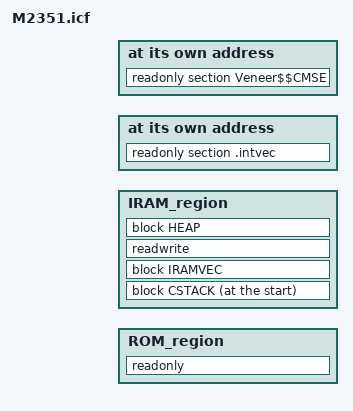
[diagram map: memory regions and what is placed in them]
/*
 * Copyright (c) 2019-2020, Nuvoton Technology Corporation
 *
 * SPDX-License-Identifier: Apache-2.0
 *
 * Licensed under the Apache License, Version 2.0 (the "License");
 * you may not use this file except in compliance with the License.
 * You may obtain a copy of the License at
 *
 *     http://www.apache.org/licenses/LICENSE-2.0
 *
 * Unless required by applicable law or agreed to in writing, software
 * distributed under the License is distributed on an "AS IS" BASIS,
 * WITHOUT WARRANTIES OR CONDITIONS OF ANY KIND, either express or implied.
 * See the License for the specific language governing permissions and
 * limitations under the License.
 */

/*###ICF### Section handled by ICF editor, don't touch! ****/
/*-Editor annotation file-*/
/* IcfEditorFile="$TOOLKIT_DIR$\config\ide\IcfEditor\cortex_v1_0.xml" */

include "../partition_M2351_mem.icf";

if (! isdefinedsymbol(NU_TZ_NSC_SIZE)) {
    define symbol NU_TZ_NSC_SIZE    = 0x1000;
}

if (isdefinedsymbol(DOMAIN_NS)) {

    if (! isdefinedsymbol(MBED_APP_START)) {
        define symbol MBED_APP_START                = NU_ROM_START_NS;
    }

    if (! isdefinedsymbol(MBED_APP_SIZE)) {
        define symbol MBED_APP_SIZE                 = NU_ROM_SIZE_NS;
    }

    if (! isdefinedsymbol(MBED_RAM_APP_START)) {
        define symbol MBED_RAM_APP_START            = NU_RAM_START_NS;
    }

    if (! isdefinedsymbol(MBED_RAM_APP_SIZE)) {
        define symbol MBED_RAM_APP_SIZE             = NU_RAM_SIZE_NS;
    }

    if (! isdefinedsymbol(MBED_BOOT_STACK_SIZE)) {
        define symbol MBED_BOOT_STACK_SIZE          = 0x400;
    }
    
    /*-Specials-*/
    define symbol __ICFEDIT_intvec_start__          = MBED_APP_START;
    /*-Memory Regions-*/
    define symbol __ICFEDIT_region_ROM_start__      = MBED_APP_START;
    define symbol __ICFEDIT_region_ROM_end__        = MBED_APP_START + MBED_APP_SIZE - 1;
    define symbol __ICFEDIT_region_IRAM_start__     = MBED_RAM_APP_START;
    define symbol __ICFEDIT_region_IRAM_end__       = MBED_RAM_APP_START + MBED_RAM_APP_SIZE - 1;
    
    /*-Sizes-*/
    define symbol __ICFEDIT_size_cstack__           = MBED_BOOT_STACK_SIZE;
    define symbol __ICFEDIT_size_heap__             = 0x8000;

} else {

    if (! isdefinedsymbol(MBED_APP_START)) {
        define symbol MBED_APP_START                = NU_ROM_START_S;
    }

    if (! isdefinedsymbol(MBED_APP_SIZE)) {
        define symbol MBED_APP_SIZE                 = NU_ROM_SIZE_S;
    }

    if (! isdefinedsymbol(MBED_RAM_APP_START)) {
        define symbol MBED_RAM_APP_START            = NU_RAM_START_S;
    }

    if (! isdefinedsymbol(MBED_RAM_APP_SIZE)) {
        define symbol MBED_RAM_APP_SIZE             = NU_RAM_SIZE_S;
    }

    if (! isdefinedsymbol(MBED_BOOT_STACK_SIZE)) {
        define symbol MBED_BOOT_STACK_SIZE          = 0x400;
    }

    /* Requirements for NSC location
     *
     * 1. By IDAU, 0~0x4000 is secure. NSC can only locate in 0x4000~0x10000000.
     * 2. Greentea flash IAP uses last 4 sectors for its test. Avoid this range.
     * 3. Greentea NVSTORE uses last 2 sectors or 4KiB x 2 for its test. Avoid this range.
     * 4. NSC region size defaults to 4KiB if not defined.
     */
    if (! isdefinedsymbol(NU_TZ_NSC_START)) {
        define symbol NU_TZ_NSC_START               = MBED_APP_START + MBED_APP_SIZE - 0x2000 - NU_TZ_NSC_SIZE;
    }
    define exported symbol __NU_TZ_NSC_start__      = NU_TZ_NSC_START;
    define exported symbol __NU_TZ_NSC_size__       = NU_TZ_NSC_SIZE;

    /*-Specials-*/
    define symbol __ICFEDIT_intvec_start__          = MBED_APP_START;
    /*-Memory Regions-*/
    define symbol __ICFEDIT_region_ROM_start__      = MBED_APP_START;
    define symbol __ICFEDIT_region_ROM_end__        = MBED_APP_START + MBED_APP_SIZE - 1;
    define symbol __ICFEDIT_region_NSCROM_start__   = NU_TZ_NSC_START;
    define symbol __ICFEDIT_region_NSCROM_end__     = NU_TZ_NSC_START + NU_TZ_NSC_SIZE - 1;
    define symbol __ICFEDIT_region_IRAM_start__     = MBED_RAM_APP_START;
    define symbol __ICFEDIT_region_IRAM_end__       = MBED_RAM_APP_START + MBED_RAM_APP_SIZE - 1;

    /*-Sizes-*/
    define symbol __ICFEDIT_size_cstack__           = MBED_BOOT_STACK_SIZE;
    define symbol __ICFEDIT_size_heap__             = 0x4000;
}

/**** End of ICF editor section. ###ICF###*/


define memory mem with size = 4G;
define region ROM_region   = mem:[from __ICFEDIT_region_ROM_start__   to __ICFEDIT_region_ROM_end__];
define region IRAM_region  = mem:[from __ICFEDIT_region_IRAM_start__  to __ICFEDIT_region_IRAM_end__];

define block CSTACK    with alignment = 8, size = __ICFEDIT_size_cstack__   { };
define block HEAP      with alignment = 8, size = __ICFEDIT_size_heap__     { };
/* NOTE: Vector table base requires to be aligned to the power of vector table size. Give a safe value here. */
define block IRAMVEC   with alignment = 1024, size = 4 * (16 + 102)          { };


initialize by copy { readwrite };
do not initialize  { section .noinit };

place at address mem:__ICFEDIT_intvec_start__ { readonly section .intvec };

place in ROM_region   { readonly };
if (! isdefinedsymbol(DOMAIN_NS)) {
    place at address mem:__ICFEDIT_region_NSCROM_start__ { readonly section Veneer$$CMSE };
}
place at start of IRAM_region   { block CSTACK };
place in IRAM_region   { block IRAMVEC };
place in IRAM_region   { readwrite };
place in IRAM_region   { block HEAP };
